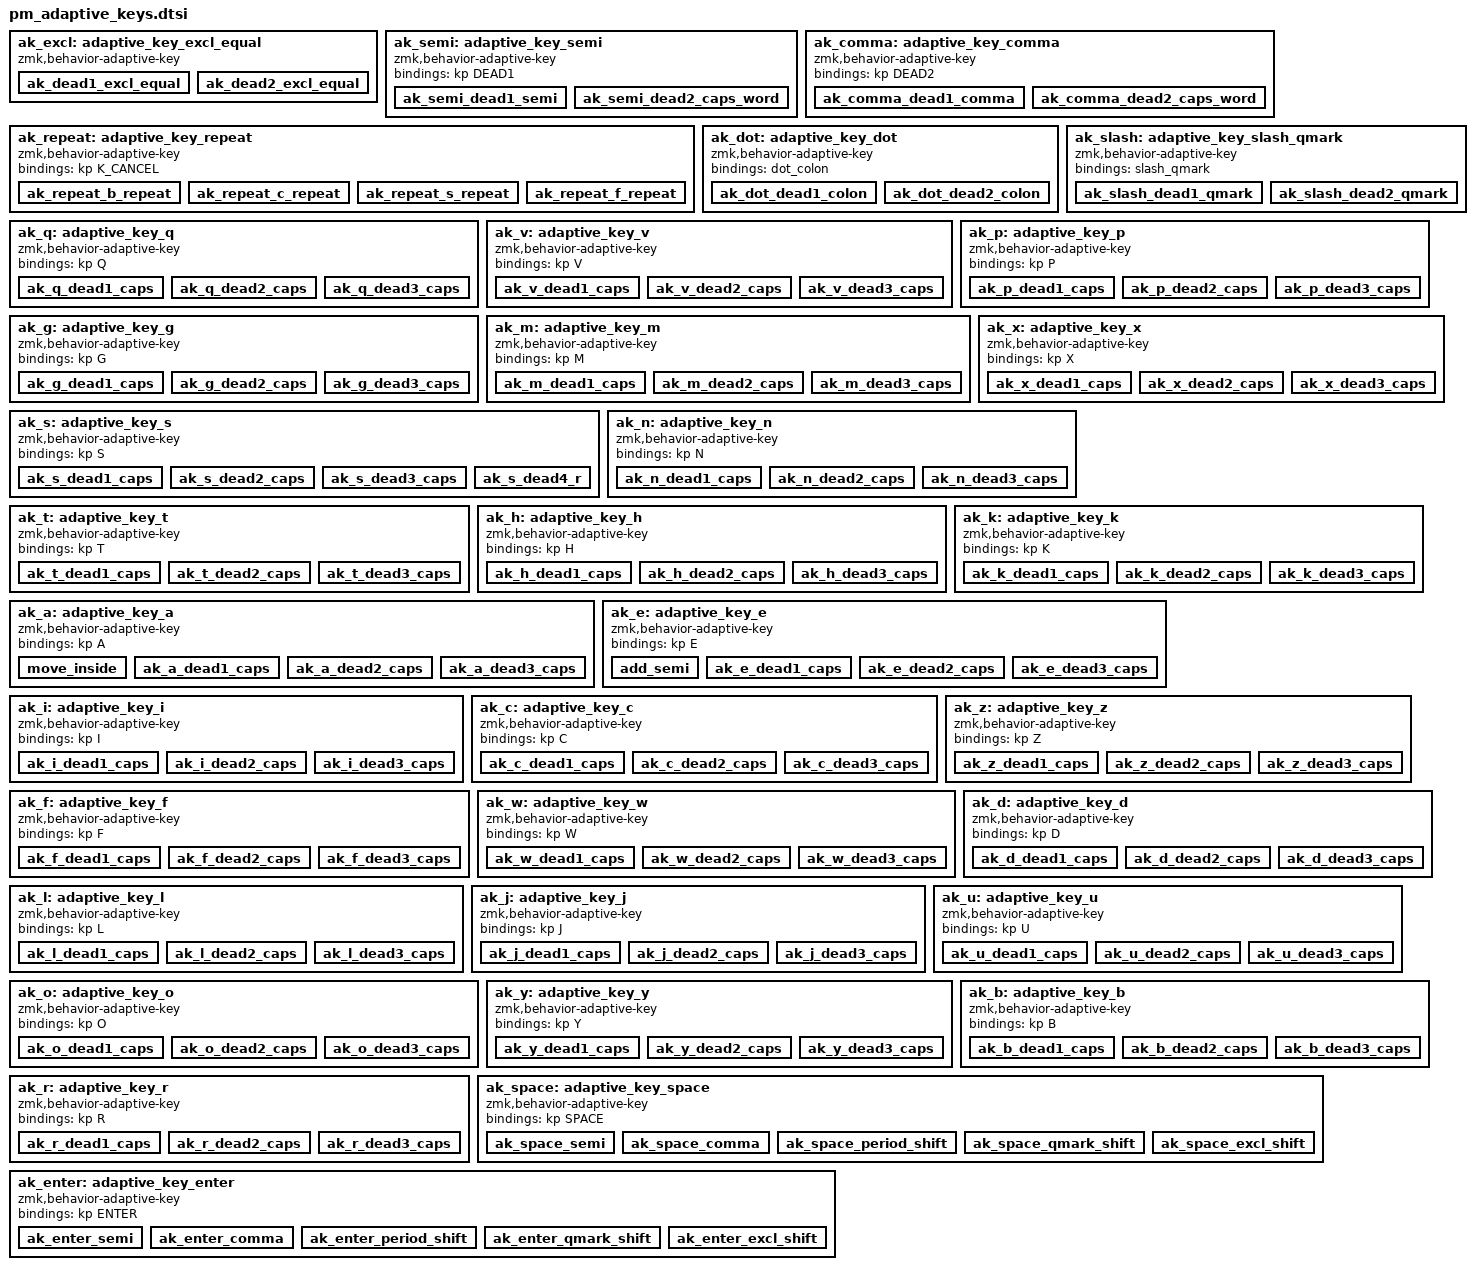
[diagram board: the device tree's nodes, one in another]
// q v p g m x s n t h k a e i c z f w d l j u o y b r
ak_excl: adaptive_key_excl_equal {
    compatible = "zmk,behavior-adaptive-key";
    #binding-cells = <0>;
    bindings = <&excl_equal>;
    // dead keys only need to be defined once, not for each behavior.
    dead-keys = <DEAD1 DEAD2 DEAD3 DEAD4>;
    
    ak_dead1_excl_equal {strict-modifiers; trigger-keys = <DEAD1>; bindings = <&kp EQUAL>; max-prior-idle-ms = <DEAD1_CAPS_PRIOR_IDLE>; };
    ak_dead2_excl_equal {strict-modifiers; trigger-keys = <DEAD2>; bindings = <&kp EQUAL>; max-prior-idle-ms = <DEAD2_CAPS_PRIOR_IDLE>; };
};

ak_semi: adaptive_key_semi {
    compatible = "zmk,behavior-adaptive-key";
    #binding-cells = <0>;
    bindings = <&kp DEAD1>;
    
    ak_semi_dead1_semi {strict-modifiers; trigger-keys = <DEAD1>; bindings = <&kp SEMI>; max-prior-idle-ms = <DEAD1_CAPS_PRIOR_IDLE>; };
    ak_semi_dead2_caps_word {strict-modifiers; trigger-keys = <DEAD2>; bindings = <&caps_word>; max-prior-idle-ms = <DEAD2_CAPS_PRIOR_IDLE>; };
};

ak_repeat: adaptive_key_repeat {
    compatible = "zmk,behavior-adaptive-key";
    #binding-cells = <0>;
    bindings = <&kp K_CANCEL>;
    
    ak_repeat_b_repeat {strict-modifiers; trigger-keys = <B>; bindings = <&kp B &kp DEAD4>; max-prior-idle-ms = <MAGIC_PRIOR_IDLE>; };
    ak_repeat_c_repeat {strict-modifiers; trigger-keys = <C>; bindings = <&kp C &kp DEAD4>; max-prior-idle-ms = <MAGIC_PRIOR_IDLE>; };
    ak_repeat_s_repeat {strict-modifiers; trigger-keys = <S>; bindings = <&kp S &kp DEAD4>; max-prior-idle-ms = <MAGIC_PRIOR_IDLE>; };
    ak_repeat_f_repeat {strict-modifiers; trigger-keys = <F>; bindings = <&kp F &kp DEAD4>; max-prior-idle-ms = <MAGIC_PRIOR_IDLE>; };
};

ak_comma: adaptive_key_comma {
    compatible = "zmk,behavior-adaptive-key";
    #binding-cells = <0>;
    bindings = <&kp DEAD2>;

    ak_comma_dead1_comma {strict-modifiers; trigger-keys = <DEAD2>; bindings = <&kp COMMA>; max-prior-idle-ms = <DEAD2_CAPS_PRIOR_IDLE>; };
    ak_comma_dead2_caps_word {strict-modifiers; trigger-keys = <DEAD1>; bindings = <&caps_word>; max-prior-idle-ms = <DEAD1_CAPS_PRIOR_IDLE>; };
};
   

ak_dot: adaptive_key_dot {
    compatible = "zmk,behavior-adaptive-key";
    #binding-cells = <0>;
    bindings = <&dot_colon>;
    
    ak_dot_dead1_colon {strict-modifiers; trigger-keys = <DEAD2>; bindings = <&kp COLON>; max-prior-idle-ms = <DEAD2_CAPS_PRIOR_IDLE>; };
    ak_dot_dead2_colon {strict-modifiers; trigger-keys = <DEAD1>; bindings = <&kp COLON>; max-prior-idle-ms = <DEAD1_CAPS_PRIOR_IDLE>; };
};

ak_slash: adaptive_key_slash_qmark {
    compatible = "zmk,behavior-adaptive-key";
    #binding-cells = <0>;
    bindings = <&slash_qmark>;
    
    ak_slash_dead1_qmark {strict-modifiers; trigger-keys = <DEAD2>; bindings = <&kp QMARK>; max-prior-idle-ms = <DEAD2_CAPS_PRIOR_IDLE>; };
    ak_slash_dead2_qmark {strict-modifiers; trigger-keys = <DEAD1>; bindings = <&kp QMARK>; max-prior-idle-ms = <DEAD1_CAPS_PRIOR_IDLE>; };
};
ak_q: adaptive_key_q {
    compatible = "zmk,behavior-adaptive-key";
    #binding-cells = <0>;
    bindings = <&kp Q>;

    ak_q_dead1_caps {strict-modifiers; trigger-keys = <DEAD1>; bindings = <&kp LS(Q)>; max-prior-idle-ms = <DEAD1_CAPS_PRIOR_IDLE>; };
    ak_q_dead2_caps {strict-modifiers; trigger-keys = <DEAD2>; bindings = <&kp LS(Q)>; max-prior-idle-ms = <DEAD2_CAPS_PRIOR_IDLE>; };
    ak_q_dead3_caps {strict-modifiers; trigger-keys = <DEAD3>; bindings = <&kp LS(Q)>; max-prior-idle-ms = <DEAD3_CAPS_PRIOR_IDLE>; };
};

ak_v: adaptive_key_v {
    compatible = "zmk,behavior-adaptive-key";
    #binding-cells = <0>;
    bindings = <&kp V>;
    
    ak_v_dead1_caps {strict-modifiers; trigger-keys = <DEAD1>; bindings = <&kp LS(V)>; max-prior-idle-ms = <DEAD1_CAPS_PRIOR_IDLE>; };
    ak_v_dead2_caps {strict-modifiers; trigger-keys = <DEAD2>; bindings = <&kp LS(V)>; max-prior-idle-ms = <DEAD2_CAPS_PRIOR_IDLE>; };
    ak_v_dead3_caps {strict-modifiers; trigger-keys = <DEAD3>; bindings = <&kp LS(V)>; max-prior-idle-ms = <DEAD3_CAPS_PRIOR_IDLE>; };
};

ak_p: adaptive_key_p {
    compatible = "zmk,behavior-adaptive-key";
    #binding-cells = <0>;
    bindings = <&kp P>;
    
    ak_p_dead1_caps {strict-modifiers; trigger-keys = <DEAD1>; bindings = <&kp LS(P)>; max-prior-idle-ms = <DEAD1_CAPS_PRIOR_IDLE>; };
    ak_p_dead2_caps {strict-modifiers; trigger-keys = <DEAD2>; bindings = <&kp LS(P)>; max-prior-idle-ms = <DEAD2_CAPS_PRIOR_IDLE>; };
    ak_p_dead3_caps {strict-modifiers; trigger-keys = <DEAD3>; bindings = <&kp LS(P)>; max-prior-idle-ms = <DEAD3_CAPS_PRIOR_IDLE>; };
};

ak_g: adaptive_key_g {
    compatible = "zmk,behavior-adaptive-key";
    #binding-cells = <0>;
    bindings = <&kp G>;
    
    ak_g_dead1_caps {strict-modifiers; trigger-keys = <DEAD1>; bindings = <&kp LS(G)>; max-prior-idle-ms = <DEAD1_CAPS_PRIOR_IDLE>; };
    ak_g_dead2_caps {strict-modifiers; trigger-keys = <DEAD2>; bindings = <&kp LS(G)>; max-prior-idle-ms = <DEAD2_CAPS_PRIOR_IDLE>; };
    ak_g_dead3_caps {strict-modifiers; trigger-keys = <DEAD3>; bindings = <&kp LS(G)>; max-prior-idle-ms = <DEAD3_CAPS_PRIOR_IDLE>; };
};

ak_m: adaptive_key_m {
    compatible = "zmk,behavior-adaptive-key";
    #binding-cells = <0>;
    bindings = <&kp M>;
    
    ak_m_dead1_caps {strict-modifiers; trigger-keys = <DEAD1>; bindings = <&kp LS(M)>; max-prior-idle-ms = <DEAD1_CAPS_PRIOR_IDLE>;};
    ak_m_dead2_caps {strict-modifiers; trigger-keys = <DEAD2>; bindings = <&kp LS(M)>; max-prior-idle-ms = <DEAD2_CAPS_PRIOR_IDLE>; };
    ak_m_dead3_caps {strict-modifiers; trigger-keys = <DEAD3>; bindings = <&kp LS(M)>; max-prior-idle-ms = <DEAD3_CAPS_PRIOR_IDLE>; };
};

ak_x: adaptive_key_x {
    compatible = "zmk,behavior-adaptive-key";
    #binding-cells = <0>;
    bindings = <&kp X>;
    
    ak_x_dead1_caps {strict-modifiers; trigger-keys = <DEAD1>; bindings = <&kp LS(X)>; max-prior-idle-ms = <DEAD1_CAPS_PRIOR_IDLE>; };
    ak_x_dead2_caps {strict-modifiers; trigger-keys = <DEAD2>; bindings = <&kp LS(X)>; max-prior-idle-ms = <DEAD2_CAPS_PRIOR_IDLE>; };
    ak_x_dead3_caps {strict-modifiers; trigger-keys = <DEAD3>; bindings = <&kp LS(X)>; max-prior-idle-ms = <DEAD3_CAPS_PRIOR_IDLE>; };
};

ak_s: adaptive_key_s {
    compatible = "zmk,behavior-adaptive-key";
    #binding-cells = <0>;
    bindings = <&kp S>;
    
    ak_s_dead1_caps {strict-modifiers; trigger-keys = <DEAD1>; bindings = <&kp LS(S)>; max-prior-idle-ms = <DEAD1_CAPS_PRIOR_IDLE>; };
    ak_s_dead2_caps {strict-modifiers; trigger-keys = <DEAD2>; bindings = <&kp LS(S)>; max-prior-idle-ms = <DEAD2_CAPS_PRIOR_IDLE>; };
    ak_s_dead3_caps {strict-modifiers; trigger-keys = <DEAD3>; bindings = <&kp LS(S)>; max-prior-idle-ms = <DEAD3_CAPS_PRIOR_IDLE>; };
    ak_s_dead4_r {strict-modifiers; trigger-keys = <DEAD4>; bindings = <&kp R>; max-prior-idle-ms = <MAGIC_PRIOR_IDLE>; };
};

ak_n: adaptive_key_n {
    compatible = "zmk,behavior-adaptive-key";
    #binding-cells = <0>;
    bindings = <&kp N>;
    
    ak_n_dead1_caps {strict-modifiers; trigger-keys = <DEAD1>; bindings = <&kp LS(N)>; max-prior-idle-ms = <DEAD1_CAPS_PRIOR_IDLE>;  };
    ak_n_dead2_caps {strict-modifiers; trigger-keys = <DEAD2>; bindings = <&kp LS(N)>; max-prior-idle-ms = <DEAD2_CAPS_PRIOR_IDLE>;  };
    ak_n_dead3_caps {strict-modifiers; trigger-keys = <DEAD3>; bindings = <&kp LS(N)>; max-prior-idle-ms = <DEAD3_CAPS_PRIOR_IDLE>;  };
};

ak_t: adaptive_key_t {
    compatible = "zmk,behavior-adaptive-key";
    #binding-cells = <0>;
    bindings = <&kp T>;
    
    ak_t_dead1_caps {strict-modifiers; trigger-keys = <DEAD1>; bindings = <&kp LS(T)>; max-prior-idle-ms = <DEAD1_CAPS_PRIOR_IDLE>; };
    ak_t_dead2_caps {strict-modifiers; trigger-keys = <DEAD2>; bindings = <&kp LS(T)>; max-prior-idle-ms = <DEAD2_CAPS_PRIOR_IDLE>; };
    ak_t_dead3_caps {strict-modifiers; trigger-keys = <DEAD3>; bindings = <&kp LS(T)>; max-prior-idle-ms = <DEAD3_CAPS_PRIOR_IDLE>; };
};

ak_h: adaptive_key_h {
    compatible = "zmk,behavior-adaptive-key";
    #binding-cells = <0>;
    bindings = <&kp H>;
    
    ak_h_dead1_caps {strict-modifiers; trigger-keys = <DEAD1>; bindings = <&kp LS(H)>; max-prior-idle-ms = <DEAD1_CAPS_PRIOR_IDLE>; };
    ak_h_dead2_caps {strict-modifiers; trigger-keys = <DEAD2>; bindings = <&kp LS(H)>; max-prior-idle-ms = <DEAD2_CAPS_PRIOR_IDLE>; };
    ak_h_dead3_caps {strict-modifiers; trigger-keys = <DEAD3>; bindings = <&kp LS(H)>; max-prior-idle-ms = <DEAD3_CAPS_PRIOR_IDLE>; };
};

ak_k: adaptive_key_k {
    compatible = "zmk,behavior-adaptive-key";
    #binding-cells = <0>;
    bindings = <&kp K>;
    
    ak_k_dead1_caps {strict-modifiers; trigger-keys = <DEAD1>; bindings = <&kp LS(K)>; max-prior-idle-ms = <DEAD1_CAPS_PRIOR_IDLE>; };
    ak_k_dead2_caps {strict-modifiers; trigger-keys = <DEAD2>; bindings = <&kp LS(K)>; max-prior-idle-ms = <DEAD2_CAPS_PRIOR_IDLE>; };
    ak_k_dead3_caps {strict-modifiers; trigger-keys = <DEAD3>; bindings = <&kp LS(K)>; max-prior-idle-ms = <DEAD3_CAPS_PRIOR_IDLE>; };
};



ak_a: adaptive_key_a {
    compatible = "zmk,behavior-adaptive-key";
    #binding-cells = <0>;
    bindings = <&kp A>;

//  I like typing closing braces/quotes/etc before filling them.         
//  This behavior moves me inside.
    move_inside {trigger-keys = <RPAR RBKT RBRC GREATER_THAN APOS DQT>; bindings = <&kp LEFT>; max-prior-idle-ms = <MAGIC_PRIOR_IDLE>; };
    ak_a_dead1_caps {strict-modifiers; trigger-keys = <DEAD1>; bindings = <&kp LS(A)>; max-prior-idle-ms = <DEAD1_CAPS_PRIOR_IDLE>; };
    ak_a_dead2_caps {strict-modifiers; trigger-keys = <DEAD2>; bindings = <&kp LS(A)>; max-prior-idle-ms = <DEAD2_CAPS_PRIOR_IDLE>; };
    ak_a_dead3_caps {strict-modifiers; trigger-keys = <DEAD3>; bindings = <&kp LS(A)>; max-prior-idle-ms = <DEAD3_CAPS_PRIOR_IDLE>; };
};

ak_e: adaptive_key_e {
    compatible = "zmk,behavior-adaptive-key";
    #binding-cells = <0>;
    bindings = <&kp E>;
//  after move_inside behavior below, this adds a semicolon and jumps back in the brackets.
    add_semi {strict-modifiers; trigger-keys = <LEFT>; bindings = <&kp RIGHT &kp SEMI &kp LEFT &kp LEFT>; max-prior-idle-ms = <MAGIC_PRIOR_IDLE>; };
    ak_e_dead1_caps {strict-modifiers; trigger-keys = <DEAD1>; bindings = <&kp LS(E)>; max-prior-idle-ms = <DEAD1_CAPS_PRIOR_IDLE>; };
    ak_e_dead2_caps {strict-modifiers; trigger-keys = <DEAD2>; bindings = <&kp LS(E)>; max-prior-idle-ms = <DEAD2_CAPS_PRIOR_IDLE>; };
    ak_e_dead3_caps {strict-modifiers; trigger-keys = <DEAD3>; bindings = <&kp LS(E)>; max-prior-idle-ms = <DEAD3_CAPS_PRIOR_IDLE>; };
};

ak_i: adaptive_key_i {
    compatible = "zmk,behavior-adaptive-key";
    #binding-cells = <0>;
    bindings = <&kp I>;
    
    ak_i_dead1_caps {strict-modifiers; trigger-keys = <DEAD1>; bindings = <&kp LS(I)>; max-prior-idle-ms = <DEAD1_CAPS_PRIOR_IDLE>; };
    ak_i_dead2_caps {strict-modifiers; trigger-keys = <DEAD2>; bindings = <&kp LS(I)>; max-prior-idle-ms = <DEAD2_CAPS_PRIOR_IDLE>; };
    ak_i_dead3_caps {strict-modifiers; trigger-keys = <DEAD3>; bindings = <&kp LS(I)>; max-prior-idle-ms = <DEAD3_CAPS_PRIOR_IDLE>; };
};

ak_c: adaptive_key_c {
    compatible = "zmk,behavior-adaptive-key";
    #binding-cells = <0>;
    bindings = <&kp C>;
    
    ak_c_dead1_caps {strict-modifiers; trigger-keys = <DEAD1>; bindings = <&kp LS(C)>; max-prior-idle-ms = <DEAD1_CAPS_PRIOR_IDLE>; };
    ak_c_dead2_caps {strict-modifiers; trigger-keys = <DEAD2>; bindings = <&kp LS(C)>; max-prior-idle-ms = <DEAD2_CAPS_PRIOR_IDLE>; };
    ak_c_dead3_caps {strict-modifiers; trigger-keys = <DEAD3>; bindings = <&kp LS(C)>; max-prior-idle-ms = <DEAD3_CAPS_PRIOR_IDLE>; };
//    ak_c_dead4_r {strict-modifiers; trigger-keys = <DEAD4>; bindings = <&kp R>; max-prior-idle-ms = <MAGIC_PRIOR_IDLE>; };
};

ak_z: adaptive_key_z {
    compatible = "zmk,behavior-adaptive-key";
    #binding-cells = <0>;
    bindings = <&kp Z>;
    
    ak_z_dead1_caps {strict-modifiers; trigger-keys = <DEAD1>; bindings = <&kp LS(Z)>; max-prior-idle-ms = <DEAD1_CAPS_PRIOR_IDLE>; };
    ak_z_dead2_caps {strict-modifiers; trigger-keys = <DEAD2>; bindings = <&kp LS(Z)>; max-prior-idle-ms = <DEAD2_CAPS_PRIOR_IDLE>; };
    ak_z_dead3_caps {strict-modifiers; trigger-keys = <DEAD3>; bindings = <&kp LS(Z)>; max-prior-idle-ms = <DEAD3_CAPS_PRIOR_IDLE>; };
};
    
ak_f: adaptive_key_f {
    compatible = "zmk,behavior-adaptive-key";
    #binding-cells = <0>;
    bindings = <&kp F>;
    
    ak_f_dead1_caps {strict-modifiers; trigger-keys = <DEAD1>; bindings = <&kp LS(F)>; max-prior-idle-ms = <DEAD1_CAPS_PRIOR_IDLE>; };
    ak_f_dead2_caps {strict-modifiers; trigger-keys = <DEAD2>; bindings = <&kp LS(F)>; max-prior-idle-ms = <DEAD2_CAPS_PRIOR_IDLE>; };
    ak_f_dead3_caps {strict-modifiers; trigger-keys = <DEAD3>; bindings = <&kp LS(F)>; max-prior-idle-ms = <DEAD3_CAPS_PRIOR_IDLE>; };
};

ak_w: adaptive_key_w {
    compatible = "zmk,behavior-adaptive-key";
    #binding-cells = <0>;
    bindings = <&kp W>;
    
    ak_w_dead1_caps {strict-modifiers; trigger-keys = <DEAD1>; bindings = <&kp LS(W)>; max-prior-idle-ms = <DEAD1_CAPS_PRIOR_IDLE>; };
    ak_w_dead2_caps {strict-modifiers; trigger-keys = <DEAD2>; bindings = <&kp LS(W)>; max-prior-idle-ms = <DEAD2_CAPS_PRIOR_IDLE>; };
    ak_w_dead3_caps {strict-modifiers; trigger-keys = <DEAD3>; bindings = <&kp LS(W)>; max-prior-idle-ms = <DEAD3_CAPS_PRIOR_IDLE>; };
};

ak_d: adaptive_key_d {
    compatible = "zmk,behavior-adaptive-key";
    #binding-cells = <0>;
    bindings = <&kp D>;
    
    ak_d_dead1_caps {strict-modifiers; trigger-keys = <DEAD1>; bindings = <&kp LS(D)>; max-prior-idle-ms = <DEAD1_CAPS_PRIOR_IDLE>; };
    ak_d_dead2_caps {strict-modifiers; trigger-keys = <DEAD2>; bindings = <&kp LS(D)>; max-prior-idle-ms = <DEAD2_CAPS_PRIOR_IDLE>; };
    ak_d_dead3_caps {strict-modifiers; trigger-keys = <DEAD3>; bindings = <&kp LS(D)>; max-prior-idle-ms = <DEAD3_CAPS_PRIOR_IDLE>; };
};

ak_l: adaptive_key_l {
    compatible = "zmk,behavior-adaptive-key";
    #binding-cells = <0>;
    bindings = <&kp L>;
    
    ak_l_dead1_caps {strict-modifiers; trigger-keys = <DEAD1>; bindings = <&kp LS(L)>; max-prior-idle-ms = <DEAD1_CAPS_PRIOR_IDLE>; };
    ak_l_dead2_caps {strict-modifiers; trigger-keys = <DEAD2>; bindings = <&kp LS(L)>; max-prior-idle-ms = <DEAD2_CAPS_PRIOR_IDLE>; };
    ak_l_dead3_caps {strict-modifiers; trigger-keys = <DEAD3>; bindings = <&kp LS(L)>; max-prior-idle-ms = <DEAD3_CAPS_PRIOR_IDLE>; };
};

ak_j: adaptive_key_j {
    compatible = "zmk,behavior-adaptive-key";
    #binding-cells = <0>;
    bindings = <&kp J>;
    
    ak_j_dead1_caps {strict-modifiers; trigger-keys = <DEAD1>; bindings = <&kp LS(J)>; max-prior-idle-ms = <DEAD1_CAPS_PRIOR_IDLE>; };
    ak_j_dead2_caps {strict-modifiers; trigger-keys = <DEAD2>; bindings = <&kp LS(J)>; max-prior-idle-ms = <DEAD2_CAPS_PRIOR_IDLE>; };
    ak_j_dead3_caps {strict-modifiers; trigger-keys = <DEAD3>; bindings = <&kp LS(J)>; max-prior-idle-ms = <DEAD3_CAPS_PRIOR_IDLE>; };
};

ak_u: adaptive_key_u {
    compatible = "zmk,behavior-adaptive-key";
    #binding-cells = <0>;
    bindings = <&kp U>;
    
    ak_u_dead1_caps {strict-modifiers; trigger-keys = <DEAD1>; bindings = <&kp LS(U)>; max-prior-idle-ms = <DEAD1_CAPS_PRIOR_IDLE>; };
    ak_u_dead2_caps {strict-modifiers; trigger-keys = <DEAD2>; bindings = <&kp LS(U)>; max-prior-idle-ms = <DEAD2_CAPS_PRIOR_IDLE>; };
    ak_u_dead3_caps {strict-modifiers; trigger-keys = <DEAD3>; bindings = <&kp LS(U)>; max-prior-idle-ms = <DEAD3_CAPS_PRIOR_IDLE>; };
};

ak_o: adaptive_key_o {
    compatible = "zmk,behavior-adaptive-key";
    #binding-cells = <0>;
    bindings = <&kp O>;
    
    ak_o_dead1_caps {strict-modifiers; trigger-keys = <DEAD1>; bindings = <&kp LS(O)>; max-prior-idle-ms = <DEAD1_CAPS_PRIOR_IDLE>; };
    ak_o_dead2_caps {strict-modifiers; trigger-keys = <DEAD2>; bindings = <&kp LS(O)>; max-prior-idle-ms = <DEAD2_CAPS_PRIOR_IDLE>; };
    ak_o_dead3_caps {strict-modifiers; trigger-keys = <DEAD3>; bindings = <&kp LS(O)>; max-prior-idle-ms = <DEAD3_CAPS_PRIOR_IDLE>; };
};

ak_y: adaptive_key_y {
    compatible = "zmk,behavior-adaptive-key";
    #binding-cells = <0>;
    bindings = <&kp Y>;
    
    ak_y_dead1_caps {strict-modifiers; trigger-keys = <DEAD1>; bindings = <&kp LS(Y)>; max-prior-idle-ms = <DEAD1_CAPS_PRIOR_IDLE>; };
    ak_y_dead2_caps {strict-modifiers; trigger-keys = <DEAD2>; bindings = <&kp LS(Y)>; max-prior-idle-ms = <DEAD2_CAPS_PRIOR_IDLE>; };
    ak_y_dead3_caps {strict-modifiers; trigger-keys = <DEAD3>; bindings = <&kp LS(Y)>; max-prior-idle-ms = <DEAD3_CAPS_PRIOR_IDLE>; };
};

ak_b: adaptive_key_b {
    compatible = "zmk,behavior-adaptive-key";
    #binding-cells = <0>;
    bindings = <&kp B>;
    
    ak_b_dead1_caps {strict-modifiers; trigger-keys = <DEAD1>; bindings = <&kp LS(B)>; max-prior-idle-ms = <DEAD1_CAPS_PRIOR_IDLE>; };
    ak_b_dead2_caps {strict-modifiers; trigger-keys = <DEAD2>; bindings = <&kp LS(B)>; max-prior-idle-ms = <DEAD2_CAPS_PRIOR_IDLE>; };
    ak_b_dead3_caps {strict-modifiers; trigger-keys = <DEAD3>; bindings = <&kp LS(B)>; max-prior-idle-ms = <DEAD3_CAPS_PRIOR_IDLE>; };
};

ak_r: adaptive_key_r {
    compatible = "zmk,behavior-adaptive-key";
    #binding-cells = <0>;
    bindings = <&kp R>;
    
    ak_r_dead1_caps {strict-modifiers; trigger-keys = <DEAD1>; bindings = <&kp LS(R)>; max-prior-idle-ms = <DEAD1_CAPS_PRIOR_IDLE>; };
    ak_r_dead2_caps {strict-modifiers; trigger-keys = <DEAD2>; bindings = <&kp LS(R)>; max-prior-idle-ms = <DEAD2_CAPS_PRIOR_IDLE>; };
    ak_r_dead3_caps {strict-modifiers; trigger-keys = <DEAD3>; bindings = <&kp LS(R)>; max-prior-idle-ms = <DEAD3_CAPS_PRIOR_IDLE>; };
};

ak_space: adaptive_key_space {
    compatible = "zmk,behavior-adaptive-key";
    #binding-cells = <0>;
    bindings = <&kp SPACE>;
    
    ak_space_semi {strict-modifiers; trigger-keys = <DEAD1>; bindings = <&kp SEMI &kp SPACE>; max-prior-idle-ms = <DEAD1_CAPS_PRIOR_IDLE>; };
    ak_space_comma {strict-modifiers; trigger-keys = <DEAD2>; bindings = <&kp COMMA &kp SPACE>; max-prior-idle-ms = <DEAD2_CAPS_PRIOR_IDLE>; };
    ak_space_period_shift {strict-modifiers; trigger-keys = <DOT>; bindings = <&kp SPACE &kp DEAD3>; max-prior-idle-ms = <MAGIC_PRIOR_IDLE>; };
    ak_space_qmark_shift {strict-modifiers; trigger-keys = <QMARK>; bindings = <&kp SPACE &kp DEAD3>; max-prior-idle-ms = <MAGIC_PRIOR_IDLE>; };
    ak_space_excl_shift {strict-modifiers; trigger-keys = <EXCL>; bindings = <&kp SPACE &kp DEAD3>; max-prior-idle-ms = <MAGIC_PRIOR_IDLE>; };
};

ak_enter: adaptive_key_enter {
    compatible = "zmk,behavior-adaptive-key";
    #binding-cells = <0>;
    bindings = <&kp ENTER>;
    
    ak_enter_semi {strict-modifiers; trigger-keys = <DEAD1>; bindings = <&kp SEMI &kp ENTER>; max-prior-idle-ms = <DEAD1_CAPS_PRIOR_IDLE>; };
    ak_enter_comma {strict-modifiers; trigger-keys = <DEAD2>; bindings = <&kp COMMA &kp ENTER>; max-prior-idle-ms = <DEAD2_CAPS_PRIOR_IDLE>; };
    ak_enter_period_shift {strict-modifiers; trigger-keys = <DOT>; bindings = <&kp ENTER &kp DEAD3>; max-prior-idle-ms = <MAGIC_PRIOR_IDLE>; };
    ak_enter_qmark_shift {strict-modifiers; trigger-keys = <QMARK>; bindings = <&kp ENTER &kp DEAD3>; max-prior-idle-ms = <MAGIC_PRIOR_IDLE>; };
    ak_enter_excl_shift {strict-modifiers; trigger-keys = <EXCL>; bindings = <&kp ENTER &kp DEAD3>; max-prior-idle-ms = <MAGIC_PRIOR_IDLE>; };
};
